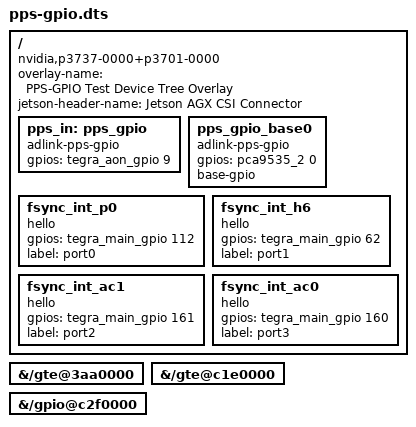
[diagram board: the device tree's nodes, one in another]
/dts-v1/;
/plugin/;

 /*
 * Copyright (c) 2017-2022, NVIDIA CORPORATION.  All rights reserved.
 *
 * This program is free software; you can redistribute it and/or modify it
 * under the terms and conditions of the GNU General Public License,
 * version 2, as published by the Free Software Foundation.
 *
 * This program is distributed in the hope it will be useful, but WITHOUT
 * ANY WARRANTY; without even the implied warranty of MERCHANTABILITY or
 * FITNESS FOR A PARTICULAR PURPOSE.  See the GNU General Public License for
 * more details.
 *
 * You should have received a copy of the GNU General Public License
 * along with this program.  If not, see <http://www.gnu.org/licenses/>.
 */


/ {
    overlay-name = "PPS-GPIO Test Device Tree Overlay";
    compatible = "nvidia,p3737-0000+p3701-0000", "nvidia,tegra234", "nvidia,tegra23x";
    jetson-header-name = "Jetson AGX CSI Connector";

    fragment@0 {
      target-path = "/";
        __overlay__ {
            pps_in: pps_gpio {
                // gpios = <&tegra_aon_gpio TEGRA234_AON_GPIO(BB, 1) GPIO_ACTIVE_LOW>;
                // => TEGRA234_AON_GPIO(BB, 1) = 1*8 + 1 = 9
                // => GPIO_ACTIVE_LOW = 1, GPIO_ACTIVE_HIGH = 0
                gpios = <&tegra_aon_gpio 9 0>;
                // interrupts-extended = <&tegra_aon_gpio 9 0>;
                
                compatible = "adlink-pps-gpio";

                // Default assert is indicated by a rising edge. 
                // Uncomment the line below to enable falling-edge assert.
                // assert-falling-edge;

                status = "okay";
            };
            
            pps_gpio_base0 {
                // base_gpio0
                gpios = <&pca9535_2 0 0>;
                compatible = "adlink-pps-gpio";

                // Default assert is indicated by a rising edge. 
                // Uncomment the line below to enable falling-edge assert.
                // assert-falling-edge;

                status = "okay";
                
                // It is a base gpio expanded from PAC953x
                base-gpio;
            };
                        
    	    fsync_int_p0 {
        		// gpios = <TEGRA234_MAIN_GPIO(P, 0) 0>;
        		// P: 14
        		// 14*8+0 = 112
    		    gpios = <&tegra_main_gpio 112 0>;
        		compatible = "hello";
    		    status = "ok";
        		label = "port0";
    	    };            
            
    	    fsync_int_h6 {
        		// gpios = <TEGRA234_MAIN_GPIO(H, 6) 0>;
        		// H: 7
        		// 7*8+6 = 62
    		    gpios = <&tegra_main_gpio 62 0>;
        		compatible = "hello";
    		    status = "ok";
    		    label = "port1";
    	    };

          fsync_int_ac1 {
        		// gpios = <TEGRA234_MAIN_GPIO(AC, 1) 0>;
        		// AC: 20
        		// 20*8+1 = 161
    		    gpios = <&tegra_main_gpio 161 0>;
        		compatible = "hello";
    		    status = "ok";
    		    label = "port2";
    	    };

    	    fsync_int_ac0 {
        		// gpios = <TEGRA234_MAIN_GPIO(AC, 1) 0>;
        		// AC: 20
        		// 20*8+0 = 160
    		    gpios = <&tegra_main_gpio 160 0>;
        		compatible = "hello";
    		    status = "ok";
    		    label = "port3";
    	    };            
            
        };
    };
    
    // following three overlays are used by GTE
    fragment@1 {
        target-path = "/gte@3aa0000";
        __overlay__ {
          status = "okay";
        };
    };
    fragment@2 {
        target-path = "/gte@c1e0000";
        __overlay__ {
          status = "okay";
        };
    };
    fragment@3 {
        target-path = "/gpio@c2f0000";
        __overlay__ {
          /delete-property/ use-timestamp;
        };
    };

};
